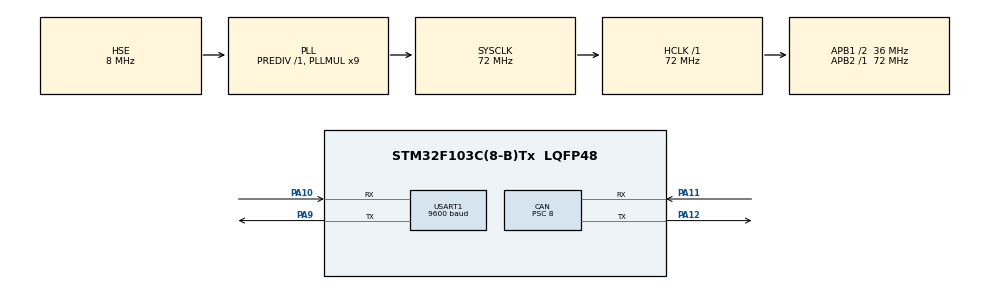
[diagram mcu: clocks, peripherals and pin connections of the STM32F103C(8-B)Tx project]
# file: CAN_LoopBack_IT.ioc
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CAN.BS1=CAN_BS1_15TQ
CAN.BS2=CAN_BS2_2TQ
CAN.CalculateBaudRate=250000
CAN.CalculateTimeBit=4000
CAN.CalculateTimeQuantum=222.22222222222223
CAN.Mode=CAN_MODE_LOOPBACK
CAN.Prescaler=8
Mcu.Family=STM32F1
Mcu.Name=STM32F103C(8-B)Tx
Mcu.Package=LQFP48
NVIC.PriorityGroup=NVIC_PRIORITYGROUP_4
PA10.Mode=Asynchronous
PA10.Signal=USART1_RX
PA11.Mode=CAN_Activate
PA11.Signal=CAN_RX
PA12.Mode=CAN_Activate
PA12.Signal=CAN_TX
PA13.Mode=Serial_Wire
PA13.Signal=SYS_JTMS-SWDIO
PA14.Mode=Serial_Wire
PA14.Signal=SYS_JTCK-SWCLK
PA9.Mode=Asynchronous
PA9.Signal=USART1_TX
PD0-OSC_IN.Mode=HSE-External-Oscillator
PD0-OSC_IN.Signal=RCC_OSC_IN
PD1-OSC_OUT.Mode=HSE-External-Oscillator
PD1-OSC_OUT.Signal=RCC_OSC_OUT
ProjectManager.HeapSize=0x200
ProjectManager.StackSize=0x400
ProjectManager.TargetToolchain=STM32CubeIDE
RCC.AHBFreq_Value=72000000
RCC.APB1CLKDivider=RCC_HCLK_DIV2
RCC.APB1Freq_Value=36000000
RCC.APB1TimFreq_Value=72000000
RCC.APB2Freq_Value=72000000
RCC.APB2TimFreq_Value=72000000
RCC.HCLKFreq_Value=72000000
RCC.PLLMUL=RCC_PLL_MUL9
RCC.PLLSourceVirtual=RCC_PLLSOURCE_HSE
RCC.SYSCLKFreq_VALUE=72000000
RCC.SYSCLKSource=RCC_SYSCLKSOURCE_PLLCLK
RCC.USBFreq_Value=72000000
USART1.BaudRate=9600
USART1.VirtualMode=VM_ASYNC
board=custom

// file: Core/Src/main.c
/* USER CODE BEGIN Header */
/**
  ******************************************************************************
  * @file           : main.c
  * @brief          : Main program body
  ******************************************************************************
  * @attention
  *
  * Copyright (c) 2023 STMicroelectronics.
  * All rights reserved.
  *
  * This software is licensed under terms that can be found in the LICENSE file
  * in the root directory of this software component.
  * If no LICENSE file comes with this software, it is provided AS-IS.
  *
  ******************************************************************************
  */
/* USER CODE END Header */
#include "main.h"
#include "stdio.h"

 CAN_HandleTypeDef hcan;

UART_HandleTypeDef huart1;

void SystemClock_Config(void);
static void MX_GPIO_Init(void);
static void MX_CAN_Init(void);
static void MX_USART1_UART_Init(void);
void CAN1_Tx(void);
void CAN1_Rx(void);
void CAN_Filter_Config(void);

int main(void)
{

  /* MCU Configuration--------------------------------------------------------*/

  /* Reset of all peripherals, Initializes the Flash interface and the Systick. */
  HAL_Init();

  /* Configure the system clock */
  SystemClock_Config();

  /* Initialize all configured peripherals */
  MX_GPIO_Init();
  MX_CAN_Init();
  MX_USART1_UART_Init();
  CAN_Filter_Config();
 if( HAL_CAN_ActivateNotification(&hcan, CAN_IT_TX_MAILBOX_EMPTY | CAN_IT_RX_FIFO0_MSG_PENDING | CAN_IT_BUSOFF) != HAL_OK )
 {
	 Error_Handler();
 }

  if(HAL_CAN_Start(&hcan) != HAL_OK)
  {
	  Error_Handler();
  }
  /* USER CODE BEGIN 2 */

  CAN1_Tx();

  /* USER CODE END 2 */

  /* Infinite loop */
  while (1)
  {

  }
}

void SystemClock_Config(void)
{
  RCC_OscInitTypeDef RCC_OscInitStruct = {0};
  RCC_ClkInitTypeDef RCC_ClkInitStruct = {0};

  /** Initializes the RCC Oscillators according to the specified parameters
  * in the RCC_OscInitTypeDef structure.
  */
  RCC_OscInitStruct.OscillatorType = RCC_OSCILLATORTYPE_HSE;
  RCC_OscInitStruct.HSEState = RCC_HSE_ON;
  RCC_OscInitStruct.HSEPredivValue = RCC_HSE_PREDIV_DIV1;
  RCC_OscInitStruct.HSIState = RCC_HSI_ON;
  RCC_OscInitStruct.PLL.PLLState = RCC_PLL_ON;
  RCC_OscInitStruct.PLL.PLLSource = RCC_PLLSOURCE_HSE;
  RCC_OscInitStruct.PLL.PLLMUL = RCC_PLL_MUL9;
  if (HAL_RCC_OscConfig(&RCC_OscInitStruct) != HAL_OK)
  {
    Error_Handler();
  }

  /** Initializes the CPU, AHB and APB buses clocks
  */
  RCC_ClkInitStruct.ClockType = RCC_CLOCKTYPE_HCLK|RCC_CLOCKTYPE_SYSCLK
                              |RCC_CLOCKTYPE_PCLK1|RCC_CLOCKTYPE_PCLK2;
  RCC_ClkInitStruct.SYSCLKSource = RCC_SYSCLKSOURCE_PLLCLK;
  RCC_ClkInitStruct.AHBCLKDivider = RCC_SYSCLK_DIV1;
  RCC_ClkInitStruct.APB1CLKDivider = RCC_HCLK_DIV2;
  RCC_ClkInitStruct.APB2CLKDivider = RCC_HCLK_DIV1;

  if (HAL_RCC_ClockConfig(&RCC_ClkInitStruct, FLASH_LATENCY_2) != HAL_OK)
  {
    Error_Handler();
  }
}

static void MX_CAN_Init(void)
{

  hcan.Instance = CAN1;
  hcan.Init.Prescaler = 8;
  hcan.Init.Mode = CAN_MODE_LOOPBACK;
  hcan.Init.SyncJumpWidth = CAN_SJW_1TQ;
  hcan.Init.TimeSeg1 = CAN_BS1_15TQ;
  hcan.Init.TimeSeg2 = CAN_BS2_2TQ;
  hcan.Init.TimeTriggeredMode = DISABLE;
  hcan.Init.AutoBusOff = DISABLE;
  hcan.Init.AutoWakeUp = DISABLE;
  hcan.Init.AutoRetransmission = ENABLE;
  hcan.Init.ReceiveFifoLocked = DISABLE;
  hcan.Init.TransmitFifoPriority = DISABLE;
  if (HAL_CAN_Init(&hcan) != HAL_OK)
  {
    Error_Handler();
  }

}

static void MX_USART1_UART_Init(void)
{

  huart1.Instance = USART1;
  huart1.Init.BaudRate = 9600;
  huart1.Init.WordLength = UART_WORDLENGTH_8B;
  huart1.Init.StopBits = UART_STOPBITS_1;
  huart1.Init.Parity = UART_PARITY_NONE;
  huart1.Init.Mode = UART_MODE_TX_RX;
  huart1.Init.HwFlowCtl = UART_HWCONTROL_NONE;
  huart1.Init.OverSampling = UART_OVERSAMPLING_16;
  if (HAL_UART_Init(&huart1) != HAL_OK)
  {
    Error_Handler();
  }

}

	uint8_t ledno = 0;

void CAN1_Tx(void)
{
	CAN_TxHeaderTypeDef TxHeader;

	uint32_t TxMailbox;

	uint8_t ourMessage;
	TxHeader.DLC = 1;
	TxHeader.StdId = 0x65D;
	TxHeader.IDE = CAN_ID_STD;
	TxHeader.RTR = CAN_RTR_DATA;

	ourMessage = ++ledno;

	if(ledno == 4)
	{
		ledno=0;
	}

	HAL_GPIO_TogglePin(GPIOC, GPIO_PIN_13);

	if(HAL_CAN_AddTxMessage(&hcan,&TxHeader,ourMessage,&TxMailbox) != HAL_OK)
	{
		Error_Handler();
	}

}

void CAN1_Rx()

{
	CAN_RxHeaderTypeDef RxHeader;

	uint8_t rcvdMsg[5];

	char msg[50];

	if(HAL_CAN_GetRxMessage(&hcan, CAN_RX_FIFO0, &RxHeader, rcvdMsg) != HAL_OK )
	{
		Error_Handler();
	}

    sprintf(msg,"Message Received: %s\r\n",rcvdMsg);

}

void CAN_Filter_Config(void)
{
	CAN_FilterTypeDef can1_filter_init;

	can1_filter_init.FilterActivation = ENABLE;
	can1_filter_init.FilterBank = 0;
	can1_filter_init.FilterFIFOAssignment = 0;
	can1_filter_init.FilterIdHigh = 0x0000;
	can1_filter_init.FilterIdLow = 0x0000;
	can1_filter_init.FilterMaskIdHigh = 0x0000;
	can1_filter_init.FilterMaskIdLow = 0x0000;
	can1_filter_init.FilterMode = CAN_FILTERMODE_IDMASK;
	can1_filter_init.FilterScale = CAN_FILTERSCALE_32BIT;

	if(HAL_CAN_ConfigFilter(&hcan,&can1_filter_init) != HAL_OK )
	{
		Error_Handler();
	}

}

static void MX_GPIO_Init(void)
{

  /* GPIO Ports Clock Enable */
  __HAL_RCC_GPIOD_CLK_ENABLE();
  __HAL_RCC_GPIOA_CLK_ENABLE();

}

void HAL_CAN_TxMailbox0CompleteCallback(CAN_HandleTypeDef *hcan)
{
	char msg[50];
	sprintf(msg,"Message Transmitted\r\n");
}
void HAL_CAN_TxMailbox1CompleteCallback(CAN_HandleTypeDef *hcan)
{
	char msg[50];
	sprintf(msg,"Message Transmitted\r\n");
}
void HAL_CAN_TxMailbox2CompleteCallback(CAN_HandleTypeDef *hcan)
{
	char msg[50];
	sprintf(msg,"Message Transmitted\r\n");
}
void HAL_CAN_RxFifo0MsgPendingCallback(CAN_HandleTypeDef *hcan)
{
	CAN_RxHeaderTypeDef RxHeader;

		uint8_t rcvdMsg[5];

		char msg[50];

		if(HAL_CAN_GetRxMessage(&hcan, CAN_RX_FIFO0, &RxHeader, rcvdMsg) != HAL_OK )
		{
			Error_Handler();
		}

	    sprintf(msg,"Message Received: %s\r\n",rcvdMsg);

}
void HAL_CAN_ErrorCallback(CAN_HandleTypeDef *hcan)
{

}

void Error_Handler(void)
{
  __disable_irq();
  while (1)
  {
  }
}
